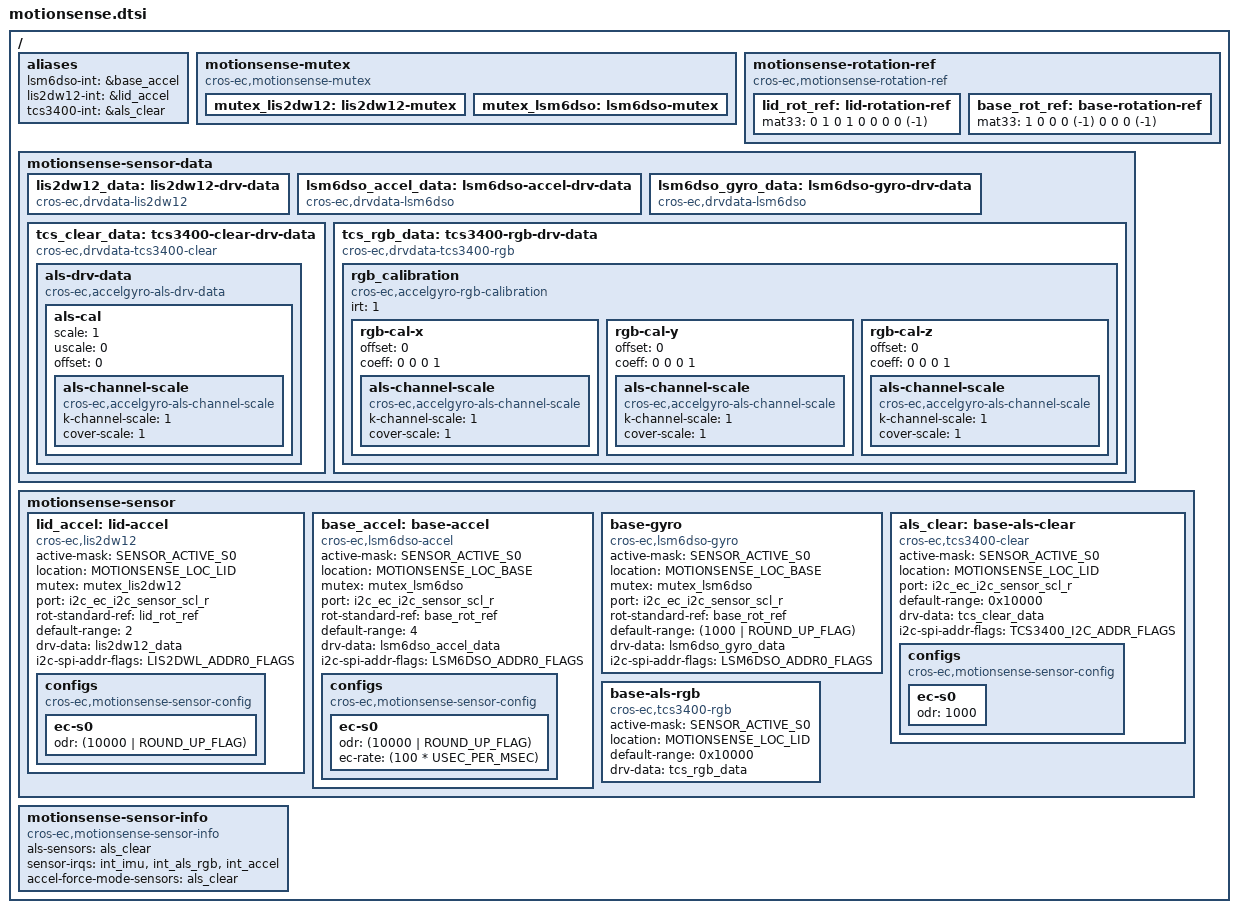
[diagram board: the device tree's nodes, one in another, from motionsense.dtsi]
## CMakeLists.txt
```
# Copyright 2023 The ChromiumOS Authors
# Use of this source code is governed by a BSD-style license that can be
# found in the LICENSE file.

zephyr_library_sources("src/board_tablet_mode.c")
```

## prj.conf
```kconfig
# Copyright 2023 The ChromiumOS Authors
# Use of this source code is governed by a BSD-style license that can be
# found in the LICENSE file.

# Fix compile issue
CONFIG_CROS_EC_RAM_BASE=0xff216900
CONFIG_CROS_EC_RAM_SIZE=0x00015000
CONFIG_CROS_EC_DATA_RAM_SIZE=0x00010000
CONFIG_CROS_EC_PROGRAM_MEMORY_BASE=0x10090000
CONFIG_CROS_EC_RO_MEM_OFF=0x0
CONFIG_CROS_EC_RO_SIZE=0xb000
CONFIG_CROS_EC_RW_MEM_OFF=0xb000
CONFIG_CROS_EC_RW_SIZE=0x75000

CONFIG_PLATFORM_EC=y
CONFIG_CROS_EC=y
CONFIG_SHIMMED_TASKS=y
CONFIG_SYSCON=y

# Disable default features
CONFIG_NAMED_ADC_CHANNELS=n
CONFIG_PWM=n
CONFIG_PLATFORM_EC_BACKLIGHT_LID=n
CONFIG_PLATFORM_EC_KEYBOARD=n
CONFIG_PLATFORM_EC_POWER_BUTTON=n
CONFIG_PLATFORM_EC_SWITCH=n
CONFIG_PLATFORM_EC_VBOOT_EFS2=n
CONFIG_PLATFORM_EC_VBOOT_HASH=n
CONFIG_PLATFORM_EC_PANIC=n
CONFIG_PLATFORM_EC_CBI_GPIO=n
CONFIG_BOARD_REX_USBC_CONFIG=n
CONFIG_LTO=n

# Log
CONFIG_LOG=y
CONFIG_LOG_MODE_MINIMAL=y

# Host Interface and  MKBP event
CONFIG_PLATFORM_EC_HOST_INTERFACE_HECI=y
CONFIG_PLATFORM_EC_MKBP_EVENT=y
CONFIG_PLATFORM_EC_MKBP_USE_HECI=y

# ISH BSP config
CONFIG_IPM=y
CONFIG_HECI=y
CONFIG_HOST_SERVICE=y
CONFIG_HECI_INTF_IPM=y
CONFIG_REBOOT=y
CONFIG_SPI=n
CONFIG_GPIO=y

#ISH PM
CONFIG_PM=y
CONFIG_PM_DEVICE=y
CONFIG_PM_DEVICE_RUNTIME=n
CONFIG_GDT_DYNAMIC=y
CONFIG_GDT_RESERVED_NUM_ENTRIES=3
CONFIG_PLATFORM_EC_CONSOLE_CMD_SLEEPMASK=n

# Other
CONFIG_SHELL_PROMPT_UART="ish:~$ "
CONFIG_SHELL_BACKEND_SERIAL_INTERRUPT_DRIVEN=n
CONFIG_SHELL_BACKEND_SERIAL_RX_POLL_PERIOD=60000

# Sensor Console Commands
CONFIG_PLATFORM_EC_CONSOLE_CMD_ACCELS=y
CONFIG_PLATFORM_EC_CONSOLE_CMD_ACCEL_INFO=y
CONFIG_PLATFORM_EC_CONSOLE_CMD_I2C_SPEED=y

# Sensor Feature Configs
CONFIG_PLATFORM_EC_ACCEL_FIFO=y
CONFIG_PLATFORM_EC_DYNAMIC_MOTION_SENSOR_COUNT=y
CONFIG_PLATFORM_EC_LID_ANGLE=y
CONFIG_PLATFORM_EC_LID_ANGLE_UPDATE=y
CONFIG_PLATFORM_EC_SENSOR_TIGHT_TIMESTAMPS=y
CONFIG_PLATFORM_EC_GMR_TABLET_MODE=y
CONFIG_PLATFORM_EC_TABLET_MODE=y
CONFIG_PLATFORM_EC_TABLET_MODE_SWITCH=y
CONFIG_PLATFORM_EC_LID_SWITCH=y

# Sensor Drivers
CONFIG_PLATFORM_EC_ACCEL_LIS2DW12=y

# Notify EC for clamshell/tablet mode change
CONFIG_PLATFORM_EC_EXTERNAL_NOTEBOOK_MODE=y
```

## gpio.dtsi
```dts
/* Copyright 2023 The ChromiumOS Authors
 * Use of this source code is governed by a BSD-style license that can be
 * found in the LICENSE file.
 */
#include <dt-bindings/gpio_defines.h>

/ {

	aliases {
		gpio-nb-mode = &gpio_soc_ec_ish_nb_mode_l;
	};

	named-gpios {
		compatible = "named-gpios";

		gpio_ec_accel_int_r_l: ec_accel_int_r_l {
			gpios = <&gpio0 3 GPIO_INPUT>;
		};
		gpio_ec_imu_int_r_l: ec_imu_int_r_l {
			gpios = <&gpio0 11 GPIO_INPUT_PULL_UP>;
		};
		gpio_ec_als_rgb_int_r_l: ec_als_rgb_int_r_l {
			gpios = <&gpio0 8 GPIO_INPUT_PULL_UP>;
		};
		gpio_ec_lid_open_int_r_l: ec_lid_open_int_r_l {
			gpios = <&gpio0 9 GPIO_INPUT>;
			enum-name = "GPIO_LID_OPEN";
		};
		gpio_ec_tablet_mode_int_r_l: ec_tablet_mode_int_r_l {
			gpios = <&gpio0 5 GPIO_INPUT>;
			enum-name = "GPIO_TABLET_MODE_L";
		};
		gpio_soc_ec_ish_nb_mode_l: soc_ec_ish_nb_mode_l {
			gpios = <&gpio0 10 GPIO_OUTPUT_LOW>;
		};
		ec_entering_rw {
			enum-name = "GPIO_ENTERING_RW";
		};

	};
};
```

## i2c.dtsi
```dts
/* Copyright 2023 The ChromiumOS Authors
 * Use of this source code is governed by a BSD-style license that can be
 * found in the LICENSE file.
 */

/ {
	aliases {
		i2c-0 = &i2c0;
	};

	named-i2c-ports {
		compatible = "named-i2c-ports";
		i2c_ec_i2c_sensor_scl_r: sensor {
			i2c-port = <&i2c0>;
			enum-names = "I2C_PORT_SENSOR";
		};
	};
};

// &i2c0 {
// 	status = "okay";

// 	// add the nuvoton 
// 	nuvoton_ec: nuvoton-ec@86 {
// 		compatible = "nuvoton,npcx99";
// 		reg = <0x86>;
// 		label = "nuvoton_npcx99_ec";
// 		// label = "i2c-device";
// 		// do I need to indicate a pin
// 		// port = <& idk >;
// 		// pinctrl-0 = <& idk >;
// 		// pinctrl-names = "default";
// 	};
// };
```

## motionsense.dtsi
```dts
/*
 * Copyright 2022 The ChromiumOS Authors
 *
 * SPDX-License-Identifier: Apache-2.0
 */

#include <dt-bindings/motionsense/utils.h>


/ {
	aliases {
		/*
		 * motion sense's <>_INT_EVENT is handled
		 * by alias. Using the alias, each driver creates
		 * its own <>_INT_EVENT.
		 */
		lsm6dso-int = &base_accel;
		lis2dw12-int = &lid_accel;
		tcs3400-int = &als_clear;
	};

	/*
	 * Declare mutexes used by sensor drivers.
	 * A mutex node is used to create an instance of mutex_t.
	 * A mutex node is referenced by a sensor node if the
	 * corresponding sensor driver needs to use the
	 * instance of the mutex.
	 */
	motionsense-mutex {
		compatible = "cros-ec,motionsense-mutex";
		mutex_lis2dw12: lis2dw12-mutex {
		};

		mutex_lsm6dso: lsm6dso-mutex {
		};
	};

	/* Rotation matrix used by drivers. */
	motionsense-rotation-ref {
		compatible = "cros-ec,motionsense-rotation-ref";
		lid_rot_ref: lid-rotation-ref {
			mat33 = <0 1 0
				 1 0 0
				 0 0 (-1)>;
		};
		base_rot_ref: base-rotation-ref {
			mat33 = <1 0 0
				 0 (-1) 0
				 0 0 (-1)>;
		};
	};

	/*
	 * Driver specific data. A driver-specific data can be shared with
	 * different motion sensors while they are using the same driver.
	 *
	 * If a node's compatible starts with "cros-ec,accelgyro-", it is for
	 * a common structure defined in accelgyro.h.
	 * e.g) compatible = "cros-ec,accelgyro-als-drv-data" is for
	 * "struct als_drv_data_t" in accelgyro.h
	 */
	motionsense-sensor-data {
		lis2dw12_data: lis2dw12-drv-data {
			compatible = "cros-ec,drvdata-lis2dw12";
			status = "okay";
		};

		lsm6dso_accel_data: lsm6dso-accel-drv-data {
			compatible = "cros-ec,drvdata-lsm6dso";
			status = "okay";
		};

		lsm6dso_gyro_data: lsm6dso-gyro-drv-data {
			compatible = "cros-ec,drvdata-lsm6dso";
			status = "okay";
		};

		tcs_clear_data: tcs3400-clear-drv-data {
			compatible = "cros-ec,drvdata-tcs3400-clear";
			status = "okay";

			als-drv-data {
				compatible = "cros-ec,accelgyro-als-drv-data";
				als-cal {
					scale = <1>;
					uscale = <0>;
					offset = <0>;
					als-channel-scale {
					compatible =
					"cros-ec,accelgyro-als-channel-scale";
						k-channel-scale = <1>;
						cover-scale = <1>;
					};
				};
			};
		};

		tcs_rgb_data: tcs3400-rgb-drv-data {
			compatible = "cros-ec,drvdata-tcs3400-rgb";
			status = "okay";

			/* node for rgb_calibration_t defined in accelgyro.h */
			rgb_calibration {
				compatible =
					"cros-ec,accelgyro-rgb-calibration";

				irt = <1>;

				rgb-cal-x {
					offset = <0>;
					coeff = <0 0 0 1>;
					als-channel-scale {
					compatible =
					"cros-ec,accelgyro-als-channel-scale";
						k-channel-scale = <1>;
						cover-scale = <1>;
					};
				};
				rgb-cal-y {
					offset = <0>;
					coeff = <0 0 0 1>;
					als-channel-scale {
					compatible =
					"cros-ec,accelgyro-als-channel-scale";
						k-channel-scale = <1>;
						cover-scale = <1>;
					};
				};
				rgb-cal-z {
					offset = <0>;
					coeff = <0 0 0 1>;
					als-channel-scale {
					compatible =
					"cros-ec,accelgyro-als-channel-scale";
						k-channel-scale = <1>;
						cover-scale = <1>;
					};
				};
			};
		};
	};

	/*
	 * List of motion sensors that creates motion_sensors array.
	 * The nodelabel "lid_accel" and "base_accel" are used to indicate
	 * motion sensor IDs for lid angle calculation.
	 */
	motionsense-sensor {
		lid_accel: lid-accel {
			compatible = "cros-ec,lis2dw12";
			status = "okay";

			active-mask = "SENSOR_ACTIVE_S0";
			location = "MOTIONSENSE_LOC_LID";
			mutex = <&mutex_lis2dw12>;
			port = <&i2c_ec_i2c_sensor_scl_r>;
			rot-standard-ref = <&lid_rot_ref>;
			default-range = <2>;
			drv-data = <&lis2dw12_data>;
			i2c-spi-addr-flags = "LIS2DWL_ADDR0_FLAGS";
			configs {
				compatible =
					"cros-ec,motionsense-sensor-config";
				ec-s0 {
					odr = <(10000 | ROUND_UP_FLAG)>;
				};
			};
		};

		base_accel: base-accel {
			compatible = "cros-ec,lsm6dso-accel";
			status = "okay";

			active-mask = "SENSOR_ACTIVE_S0";
			location = "MOTIONSENSE_LOC_BASE";
			mutex = <&mutex_lsm6dso>;
			port = <&i2c_ec_i2c_sensor_scl_r>;
			rot-standard-ref = <&base_rot_ref>;
			default-range = <4>;
			drv-data = <&lsm6dso_accel_data>;
			i2c-spi-addr-flags = "LSM6DSO_ADDR0_FLAGS";
			configs {
				compatible =
					"cros-ec,motionsense-sensor-config";
				ec-s0 {
					odr = <(10000 | ROUND_UP_FLAG)>;
					ec-rate = <(100 * USEC_PER_MSEC)>;
				};
			};
		};

		base-gyro {
			compatible = "cros-ec,lsm6dso-gyro";
			status = "okay";

			active-mask = "SENSOR_ACTIVE_S0";
			location = "MOTIONSENSE_LOC_BASE";
			mutex = <&mutex_lsm6dso>;
			port = <&i2c_ec_i2c_sensor_scl_r>;
			rot-standard-ref = <&base_rot_ref>;
			default-range = <(1000 | ROUND_UP_FLAG)>; /* dps */
			drv-data = <&lsm6dso_gyro_data>;
			i2c-spi-addr-flags = "LSM6DSO_ADDR0_FLAGS";
		};

		als_clear: base-als-clear {
			compatible = "cros-ec,tcs3400-clear";
			status = "okay";

			active-mask = "SENSOR_ACTIVE_S0";
			location = "MOTIONSENSE_LOC_LID";
			port = <&i2c_ec_i2c_sensor_scl_r>;
			default-range = <0x10000>;
			drv-data = <&tcs_clear_data>;
			i2c-spi-addr-flags = "TCS3400_I2C_ADDR_FLAGS";
			configs {
				compatible =
					"cros-ec,motionsense-sensor-config";
				ec-s0 {
					/* Run ALS sensor in S0 */
					odr = <1000>;
				};
			};
		};

		base-als-rgb {
			compatible = "cros-ec,tcs3400-rgb";
			status = "okay";

			active-mask = "SENSOR_ACTIVE_S0";
			location = "MOTIONSENSE_LOC_LID";
			default-range = <0x10000>; /* scale = 1x, uscale = 0 */
			drv-data = <&tcs_rgb_data>;
		};
	};

	motionsense-sensor-info {
		compatible = "cros-ec,motionsense-sensor-info";

		/* list of entries for motion_als_sensors */
		als-sensors = <&als_clear>;
		/*
		 * list of GPIO interrupts that have to
		 * be enabled at initial stage
		 */
		sensor-irqs = <&int_imu &int_als_rgb &int_accel>;
		/* list of sensors in force mode */
		accel-force-mode-sensors = <&als_clear>;
	};
};
```

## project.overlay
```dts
/* Copyright 2023 The ChromiumOS Authors
 * Use of this source code is governed by a BSD-style license that can be
 * found in the LICENSE file.
 */

/* rex-ish project DTSI includes */
#include "gpio.dtsi"
#include "i2c.dtsi"
#include "interrupts.dtsi"
#include "ish.dtsi"
#include <program/rex/motionsense.dtsi>

&lid_accel {
	active-mask = "SENSOR_ACTIVE_S0";
	configs {
		/delete-node/ ec-s3;
	};
};

&base_accel {
	active-mask = "SENSOR_ACTIVE_S0";
	configs {
		/delete-node/ ec-s3;
	};
};

&base_gyro {
	active-mask = "SENSOR_ACTIVE_S0";
};

&als_clear {
	active-mask = "SENSOR_ACTIVE_S0";
};

&als_rgb {
	active-mask = "SENSOR_ACTIVE_S0";
};
```

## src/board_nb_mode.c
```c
/* Copyright 2023 The ChromiumOS Authors
 * Use of this source code is governed by a BSD-style license that can be
 * found in the LICENSE file.
 */

#include "hooks.h"
#include "tablet_mode.h"

static void board_nb_mode_change(void)
{
	/*
	 * gpio_ec_nb_mode_l is an active low pin; default level is low.
	 * This pin is an output going to EC.
	 * When system is in notebook(clamshell) mode, set pin level to low.
	 * When system is in tablet mode, set pin level to high.
	 * ISH updates this gpio to notify EC about mode change.
	 */
	gpio_pin_set_dt(GPIO_DT_FROM_NODELABEL(gpio_ec_nb_mode_l),
			tablet_get_mode());
}
DECLARE_HOOK(HOOK_TABLET_MODE_CHANGE, board_nb_mode_change, HOOK_PRIO_DEFAULT);
```

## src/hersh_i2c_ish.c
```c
/*
 * Code assumes this is the only file writing to the control register (0x52). If this isnt the case
 * i2c_reads need to be added before every i2c_write to obtain the value
 */
#include "common.h"
#include "console.h"
#include "hooks.h"
#include "printf.h"
#include "host_command.h"
#include "util.h"
#include <zephyr/device.h>
#include <zephyr/devicetree.h>
// #define CONFIG_I2C_TARGET 1
#include <zephyr/drivers/i2c.h>
// #include <i2c_npcx_controller.h>
// #include <zephyr/
// #include <i2c/i2c.h> // shimmed code at ec/zephyr/shim/include/i2c/i2c.h
// #include <zephyr/logging/log.h>


#define CPRINTF(format, args...) cprintf(CC_HERSH_I2C_ISH, format, ##args)

#define REG_LEN_BYTES 2
#define EC_CONTROL_REG  0x52
uint8_t ec_control_reg_val[REG_LEN_BYTES]; // register is 2 bytes long
uint8_t i2c_read_val[REG_LEN_BYTES]; 

#define I2C_BUS_NODE	DT_ALIAS(i2c_0)
// #define I2C_EC_NODE		DT_ALIAS(nuvoton_ec)
static uint32_t i2c_cfg = I2C_SPEED_SET(I2C_SPEED_STANDARD) | I2C_MODE_CONTROLLER;
// static const struct device *const i2c_ec;
const struct device *const i2c_0_dev = DEVICE_DT_GET(I2C_BUS_NODE);
#define EC_DEV DT_NODELABEL(nuvoton_npcx99_ec)
#if DT_NODE_HAS_STATUS(EC_DEV, okay)
	const struct device *const ec_dev = DEVICE_DT_GET(DT_NODELABEL(nuvoton_npcx99_ec));
#else
	#error "Node is disabled"
#endif
struct i2c_target_config i2c_ec_cfg;
#define EC_I2C_ADDR 0x56

bool i2c_init_success = false;


int i2c_target_error_wrapper(int (*f)(const struct device*, struct i2c_target_config*), const struct device *dev, struct i2c_target_config *cfg, const char str[]) {
	int ret;
	switch(ret = (*f)(dev, cfg)) {
		case -EINVAL:
			CPRINTF("%s parameters are invalid\n", str);
			return 1;
		case -EIO:
			CPRINTF("%s general input/output error\n", str);
			return 1;
		case -ENOSYS :
			CPRINTF("%s target mode is not implemented\n", str);
			return 1;
		case -EBUSY : 
			CPRINTF("%s atomic_test_and_set_bit returned true, or transaction is ongoing\n", str);
			return 1;
		case 0 : // target registered sucessfully 
			break;
		default:
			CPRINTF("%s Unspecified case %d, -EINVAL %d, -EIO %d, -ENOSYS %d\n", str, ret, -EINVAL, -EIO, -ENOSYS);
			return 1;
	}
	return 0;
}


void ish_i2c_init(void)
{
	uint32_t i2c_cfg_tmp;
	
	if (!device_is_ready(i2c_0_dev)) {
		CPRINTF("I2C device is not ready\n");
		return;
	}

	/* 1. Verify i2c_configure() */
	if (i2c_configure(i2c_0_dev, i2c_cfg)) {
		CPRINTF("I2C config failed\n");
		return;
	}

	/* 2. Verify i2c_get_config() */
	if (i2c_get_config(i2c_0_dev, &i2c_cfg_tmp)) {
		CPRINTF("I2C get_config failed\n");
		return;
	}
	if (i2c_cfg != i2c_cfg_tmp) {
		CPRINTF("I2C get_config returned invalid config\n");
		return;
	}

	/* 3. Register EC as Target */
	if(ec_dev == NULL) {
		CPRINTF("Failed to get EC Device Binding\n");
		return;
	}
	if(!device_is_ready(ec_dev)) {
		CPRINTF("EC I2C Device is not ready\n");
		return;
	}
	i2c_ec_cfg.address = EC_I2C_ADDR;
	if(i2c_target_error_wrapper(i2c_target_register, ec_dev, &i2c_ec_cfg, "I2C Target driver register - "))
		return;

	/* 4. initialized ec control register to 0 */
	memset(ec_control_reg_val, 0, REG_LEN_BYTES);
	i2c_init_success = true;
}
DECLARE_HOOK(HOOK_INIT, ish_i2c_init, HOOK_PRIO_DEFAULT);


bool i2c_unregister_success = false;
void i2c_unregister(void)
{
	/* Unregister EC as Target */
	if(i2c_target_error_wrapper(i2c_target_unregister, ec_dev, &i2c_ec_cfg, "I2C Target driver unregister - "))
		return;
	i2c_unregister_success = true;
}
// DECLARE_HOOK(HOOK_CHIPSET_RESET, i2c_unregister, HOOK_PRIO_DEFAULT);


static volatile int count = 0;
void i2c_test(void)
{
	if(count++%15 == 0) {
		// i2c_unregister_success = false;
		// i2c_init_success = false;
		// ish_i2c_init();
		// if(!i2c_init_success) {
		// 	CPRINTF("i2c init failure\n");
		// 	return;
		// }
		// read value of SMBus register to ensure it is set

		// if(i2c_write(ec_dev, ec_control_reg_val, REG_LEN_BYTES, EC_CONTROL_REG)) {
		// if(i2c_write(i2c_0_dev, ec_control_reg_val, REG_LEN_BYTES, EC_CONTROL_REG)) {
		if(i2c_reg_write_byte(ec_dev, EC_I2C_ADDR, EC_CONTROL_REG, 0x28 /* 0x00 */)) {
			CPRINTF("Failed to set control register to 0 via I2C\n");
			// return;
		} 
		else
			CPRINTF("Write works\n");
		
		// i2c_unregister();
		// if(!i2c_unregister_success) {
		// 	CPRINTF("i2c unregister failure\n");
		// }
	}
}
DECLARE_HOOK(HOOK_SECOND, i2c_test, HOOK_PRIO_DEFAULT);


void ec_enable_lid_interrupt(void)
{
    ec_control_reg_val[0] |= 0b01;
    i2c_write(i2c_0_dev, ec_control_reg_val, REG_LEN_BYTES, EC_CONTROL_REG);
}


void ec_disable_lid_interrupt(void)
{
    ec_control_reg_val[0] &= 0b10;
    i2c_write(i2c_0_dev, ec_control_reg_val, REG_LEN_BYTES, EC_CONTROL_REG);
}

// void test_ish_i2c(void)
// {
// 	int readret = i2c_read(i2c_ec, i2c_read_val, REG_LEN_BYTES, EC_CONTROL_REG);

//     // ec_control_reg_val[0] |= 0b01;
//     int writeret = i2c_write(i2c_ec, ec_control_reg_val, REG_LEN_BYTES, EC_CONTROL_REG);
// 	CPRINTF(
// 		"ec_control_reg: %d || I2C (Write, Read) Works: %s %s\n", 
// 		i2c_read_val[0] + i2c_read_val[1], 
// 		writeret ? "false" : "true ",
// 		readret ? "false " : "true "
// 	);
// 	ec_control_reg_val[0]++;
// }
// DECLARE_HOOK(HOOK_SECOND, test_ish_i2c, HOOK_PRIO_DEFAULT);
```
